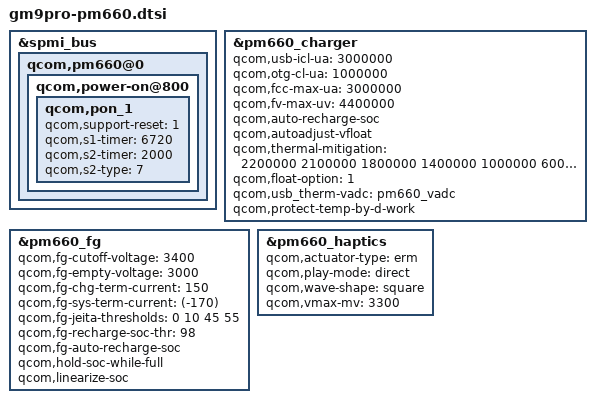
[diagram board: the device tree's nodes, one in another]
&spmi_bus {
	qcom,pm660@0 {
		qcom,power-on@800 {
			qcom,pon_1 {
				qcom,support-reset = <1>;
				qcom,s1-timer = <6720>;
				qcom,s2-timer = <2000>;
				qcom,s2-type = <7>;
			};
		};
	};
};


&pm660_charger {
	qcom,usb-icl-ua = <3000000>;
	qcom,otg-cl-ua = <1000000>;
	qcom,fcc-max-ua = <3000000>;
	qcom,fv-max-uv = <4400000>;
	qcom,auto-recharge-soc;
	qcom,autoadjust-vfloat;
	qcom,thermal-mitigation = <2200000 2100000 1800000 1400000 1000000 600000 0>;
	qcom,float-option = <1>;
	qcom,usb_therm-vadc = <&pm660_vadc>;
	qcom,protect-temp-by-d-work;
};

&pm660_fg {
	qcom,fg-cutoff-voltage = <3400>;
	qcom,fg-empty-voltage = <3000>;
	qcom,fg-chg-term-current = <150>;
	qcom,fg-sys-term-current = <(-170)>;
	qcom,fg-jeita-thresholds = <0 10 45 55>;
	qcom,fg-recharge-soc-thr = <98>;
	qcom,fg-auto-recharge-soc;
	qcom,hold-soc-while-full;
	qcom,linearize-soc;
};

&pm660_haptics {
	/delete-property/ qcom,int-pwm-freq-khz;
	/delete-property/ qcom,brake-pattern;
	/delete-property/ qcom,lra-high-z;
	/delete-property/ qcom,lra-auto-res-mode;
	/delete-property/ qcom,lra-calibrate-at-eop;
	/delete-property/ qcom,correct-lra-drive-freq;
	/delete-property/ qcom,en-brake;

	qcom,actuator-type = "erm";
	qcom,play-mode = "direct";
	qcom,wave-shape = "square";
	qcom,vmax-mv = <3300>;
};
